# STM32C5A3xx register map
File version: 1.0
Registers are 32-bit, read-write, reset 0x0 unless marked. A register's access mark holds for its fields unless they carry their own. Offsets are from the block's base; [hi:lo] are bit positions; {n}, {i} and the like mark numbered series.

## PKA — Public key accelerator (PKA)
Base 0x420C2000
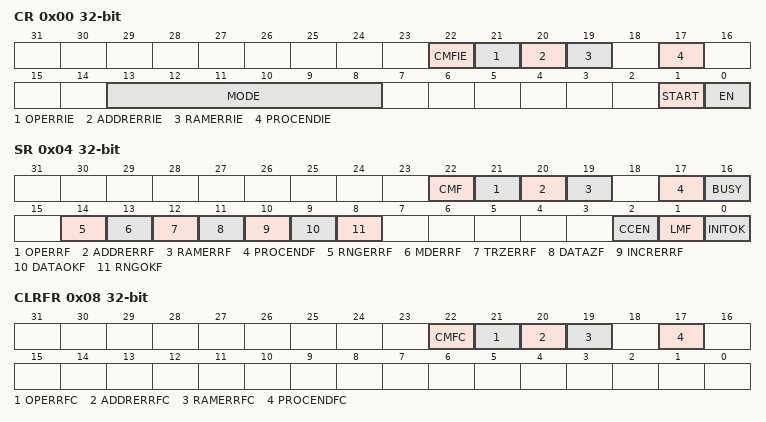
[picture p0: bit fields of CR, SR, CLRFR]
0x00 CR — PKA control register
  [22] CMFIE — Chaining mode flags interrupt enable
  [21] OPERRIE — Operation error interrupt enable
  [20] ADDRERRIE — Address error interrupt enable
  [19] RAMERRIE — RAM error interrupt enable
  [17] PROCENDIE — End of operation interrupt enable
  [13:8] MODE — PKA operation code
  [1] START — start the operation
  [0] EN — PKA enable
0x04 SR ro — PKA status register
  [22] CMF — Chaining mode flags
  [21] OPERRF — Operation error flag
  [20] ADDRERRF — Address error flag
  [19] RAMERRF — PKA RAM error flag
  [17] PROCENDF — PKA end of operation flag
  [16] BUSY — Busy flag
  [14] RNGERRF — RNG error flag
  [13] MDERRF — Mode error flag
  [12] TRZERRF — Trailing 0s error flag
  [11] DATAZF — Data 0-ed error flag
  [10] INCRERRF — Increment error flag
  [9] DATAOKF — Data OK flag
  [8] RNGOKF — RNG OK flag
  [2] CCEN — Coupling and chaining mode enable
  [1] LMF — Limited mode flag
  [0] INITOK — PKA initialization OK
0x08 CLRFR — PKA clear flag register
  [22] CMFC — Clear chaining mode flag
  [21] OPERRFC — Clear operation error flag
  [20] ADDRERRFC — Clear address error flag
  [19] RAMERRFC — Clear PKA RAM error flag
  [17] PROCENDFC — Clear PKA end of operation flag
{0x400+i} RAM[{i}] (i=0..5335) 8-bit

## CCB — Coupling and chaining bridge
Base 0x420C7C00
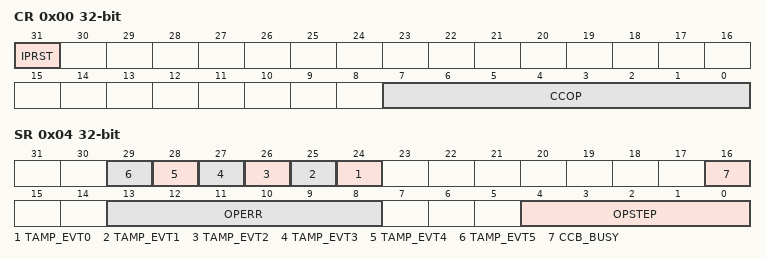
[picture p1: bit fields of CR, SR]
0x00 CR — CCB control register
  [31] IPRST — CCB reset
  [7:0] CCOP — Coupling and chaining operation
0x04 SR ro — CCB status register
  [n+24] TAMP_EVT{n} (n=0..5) — Tamper i flag
  [16] CCB_BUSY
  [13:8] OPERR — Operation error
  [4:0] OPSTEP — Operation step
{0x10+4i} REFTAGR{i} (i=0..3) — CCB reference tag register

## SBS — System configuration, boot and security (SBS)
Base 0x44000400
0x10 HDPLCR — SBS temporal isolation control register
  [7:0] INCR_HDPL
0x14 HDPLSR ro — SBS temporal isolation status register
  [7:0] HDPL
0x18 NEXTHDPLCR — SBS next HDPL control register
  [1:0] NEXTHDPL
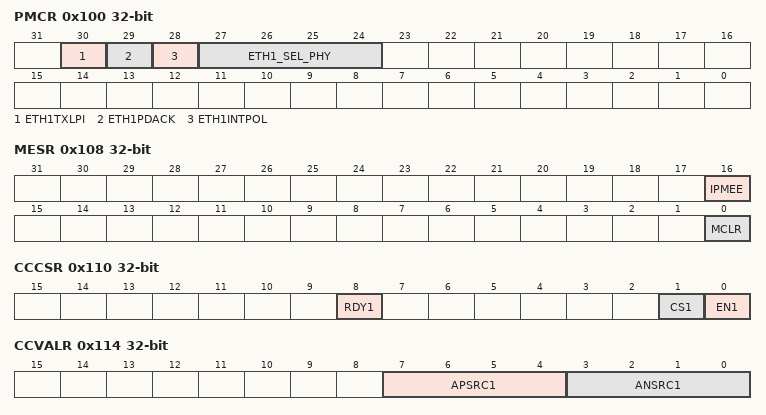
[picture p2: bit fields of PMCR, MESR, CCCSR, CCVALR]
0x100 PMCR — SBS product mode and configuration register
  [30] ETH1TXLPI, [29] ETH1PDACK, [28] ETH1INTPOL, [27:24] ETH1_SEL_PHY
0x104 FPUIMR — SBS FPU interrupt mask register
  [5:0] FPU_IE
0x108 MESR — SBS memory erase status register
  [16] IPMEE, [0] MCLR
0x110 CCCSR — SBS compensation cell for I/Os control and status register
  [8] RDY1, [1] CS1, [0] EN1
0x114 CCVALR ro — SBS compensation cell for I/Os value register
  [7:4] APSRC1, [3:0] ANSRC1
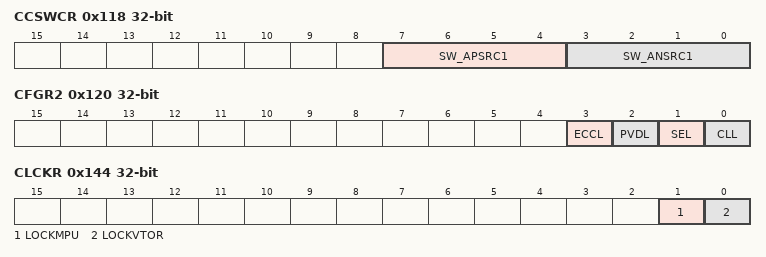
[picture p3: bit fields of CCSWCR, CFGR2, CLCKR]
0x118 CCSWCR — SBS compensation cell for I/Os software code register
  [7:4] SW_APSRC1, [3:0] SW_ANSRC1
0x120 CFGR2 — SBS Class B register
  [3] ECCL — ECC lock
  [2] PVDL — PVD lock
  [1] SEL
  [0] CLL
0x144 CLCKR — SBS CPU lock register
  [1] LOCKMPU, [0] LOCKVTOR
0x14C ECCNMIR — SBS ECC NMI mask register
  [0] ECCNMI_MASK_EN

## TAMP — Tamper and backup registers
Base 0x44007C00
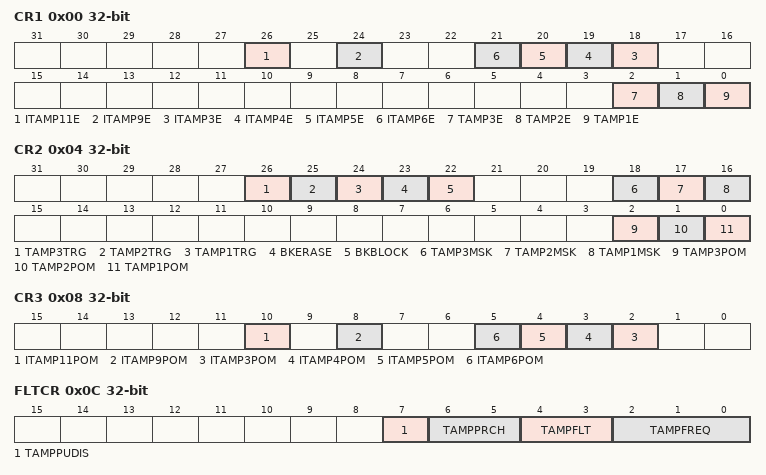
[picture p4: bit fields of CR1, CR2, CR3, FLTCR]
0x00 CR1 — TAMP control register 1
  [26] ITAMP11E — Internal tamper 11 enable
  [24] ITAMP9E — Internal tamper 9 enable
  [n+15] ITAMP{n}E (n=3..6) — Internal tamper {n} enable
  [2] TAMP3E — Tamper detection on TAMP_IN3 enable
  [1] TAMP2E — Tamper detection on TAMP_IN2 enable
  [0] TAMP1E — Tamper detection on TAMP_IN1 enable
0x04 CR2 — TAMP control register 2
  [26] TAMP3TRG — Active level for tamper 3 input
  [25] TAMP2TRG — Active level for tamper 2 input
  [24] TAMP1TRG — Active level for tamper 1 input
  [23] BKERASE — Backup registers and device secrets erase
  [22] BKBLOCK — Backup registers and device secrets access blocked
  [18] TAMP3MSK — Tamper 3 mask
  [17] TAMP2MSK — Tamper 2 mask
  [16] TAMP1MSK — Tamper 1 mask
  [2] TAMP3POM — Tamper 3 potential mode
  [1] TAMP2POM — Tamper 2 potential mode
  [0] TAMP1POM — Tamper 1 potential mode
0x08 CR3 — TAMP control register 3
  [10] ITAMP11POM — Internal tamper 11 potential mode
  [8] ITAMP9POM — Internal tamper 9 potential mode
  [n-1] ITAMP{n}POM (n=3..6) — Internal tamper {n} potential mode
0x0C FLTCR — TAMP filter control register
  [7] TAMPPUDIS — TAMP_INx pull-up disable
  [6:5] TAMPPRCH — TAMP_INx precharge duration
  [4:3] TAMPFLT — TAMP_INx filter count
  [2:0] TAMPFREQ — Tamper sampling frequency
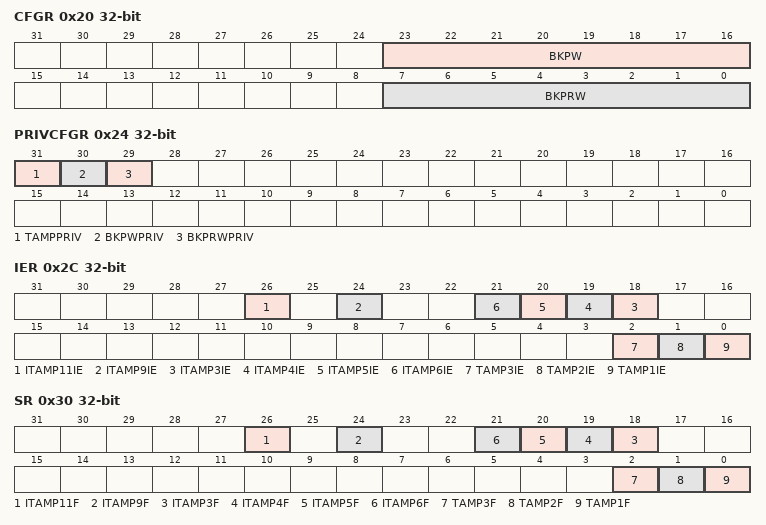
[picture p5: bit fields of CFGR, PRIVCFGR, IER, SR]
0x20 CFGR — TAMP configuration register
  [23:16] BKPW — Backup registers write protection offset
  [7:0] BKPRW — Backup registers read/write protection offset
0x24 PRIVCFGR — TAMP privilege configuration register
  [31] TAMPPRIV — Tamper privilege protection (excluding backup registers)
  [30] BKPWPRIV — Backup registers zone 2 privilege protection
  [29] BKPRWPRIV — Backup registers zone 1 privilege protection
0x2C IER — TAMP interrupt enable register
  [26] ITAMP11IE — Internal tamper 11 interrupt enable
  [24] ITAMP9IE — Internal tamper 9 interrupt enable
  [n+15] ITAMP{n}IE (n=3..6) — Internal tamper {n} interrupt enable
  [2] TAMP3IE — Tamper 3 interrupt enable
  [1] TAMP2IE — Tamper 2 interrupt enable
  [0] TAMP1IE — Tamper 1 interrupt enable
0x30 SR ro — TAMP status register
  [26] ITAMP11F — Internal tamper 11 flag
  [24] ITAMP9F — Internal tamper 9 flag
  [n+15] ITAMP{n}F (n=3..6) — Internal tamper {n} flag
  [2] TAMP3F — TAMP3 detection flag
  [1] TAMP2F — TAMP2 detection flag
  [0] TAMP1F — TAMP1 detection flag
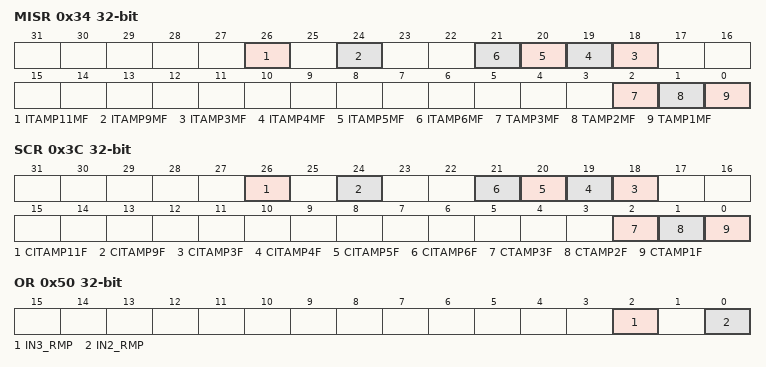
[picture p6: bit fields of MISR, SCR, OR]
0x34 MISR ro — TAMP masked interrupt status register
  [26] ITAMP11MF — internal tamper 11 interrupt masked flag
  [24] ITAMP9MF — internal tamper 9 interrupt masked flag
  [n+15] ITAMP{n}MF (n=3..6) — Internal tamper {n} interrupt masked flag
  [2] TAMP3MF — TAMP3 interrupt masked flag
  [1] TAMP2MF — TAMP2 interrupt masked flag
  [0] TAMP1MF — TAMP1 interrupt masked flag
0x3C SCR — TAMP status clear register
  [26] CITAMP11F — Clear ITAMP11 detection flag
  [24] CITAMP9F — Clear ITAMP9 detection flag
  [n+15] CITAMP{n}F (n=3..6) — Clear ITAMP{n} detection flag
  [2] CTAMP3F — Clear TAMP3 detection flag
  [1] CTAMP2F — Clear TAMP2 detection flag
  [0] CTAMP1F — Clear TAMP1 detection flag
0x50 OR — TAMP option register
  [2] IN3_RMP — TAMP_IN3 pin select
  [0] IN2_RMP — TAMP_IN2 pin select
{0x100+4i} BKP{i}R (i=0..31) — TAMP backup register {i}
  [31:0] BKP — The application can write or read data to and from these registers
